# RX64M_SYSTEM_Pilot register map
File version: 1.0
RX64M_SYSTEM_Pilot peripheral registers generated from iodefine.h (pilot).
Registers are 8-bit, read-write, reset 0x0 unless marked. A register's access mark holds for its fields unless they carry their own. Offsets are from the block's base; lines under a group give offsets from that group; [hi:lo] are bit positions; {n}, {i} and the like mark numbered series; 'fields as' and 'values as' point back to an identical list; <NAME> marks a mode.

## Memory map
0x00080000 SYSTEM size 0xC2C0

## SYSTEM
Base 0x00080000
0x00 MDMONR 16-bit ro reset not defined
  [0] MD
0x02 MDSR 16-bit ro reset not defined
  [5] UBTS
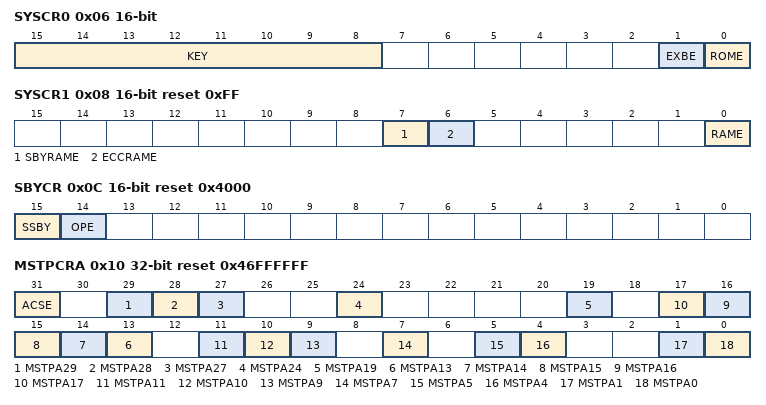
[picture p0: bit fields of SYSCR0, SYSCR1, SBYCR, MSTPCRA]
0x06 SYSCR0 16-bit reset not defined
  [15:8] KEY, [1] EXBE, [0] ROME
0x08 SYSCR1 16-bit reset 0xFF
  [7] SBYRAME, [6] ECCRAME, [0] RAME
0x0C SBYCR 16-bit reset 0x4000
  [15] SSBY, [14] OPE
0x10 MSTPCRA 32-bit reset 0x46FFFFFF
  [31] ACSE, [29] MSTPA29, [28] MSTPA28, [27] MSTPA27, [24] MSTPA24, [19] MSTPA19, [n] MSTPA{n} (n=13..17), [11] MSTPA11, [10] MSTPA10, [9] MSTPA9, [7] MSTPA7, [5] MSTPA5, [4] MSTPA4, [1] MSTPA1, [0] MSTPA0
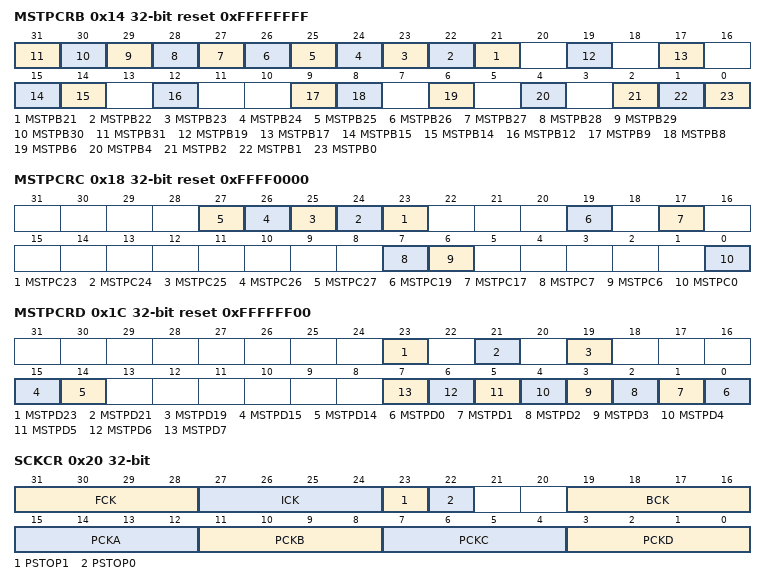
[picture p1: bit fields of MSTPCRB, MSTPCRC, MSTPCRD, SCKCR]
0x14 MSTPCRB 32-bit reset 0xFFFFFFFF
  [n] MSTPB{n} (n=21..31), [19] MSTPB19, [17] MSTPB17, [15] MSTPB15, [14] MSTPB14, [12] MSTPB12, [9] MSTPB9, [8] MSTPB8, [6] MSTPB6, [4] MSTPB4, [2] MSTPB2, [1] MSTPB1, [0] MSTPB0
0x18 MSTPCRC 32-bit reset 0xFFFF0000
  [n] MSTPC{n} (n=23..27), [19] MSTPC19, [17] MSTPC17, [7] MSTPC7, [6] MSTPC6, [0] MSTPC0
0x1C MSTPCRD 32-bit reset 0xFFFFFF00
  [23] MSTPD23, [21] MSTPD21, [19] MSTPD19, [15] MSTPD15, [14] MSTPD14, [n] MSTPD{n} (n=0..7)
0x20 SCKCR 32-bit
  [31:28] FCK, [27:24] ICK, [23] PSTOP1, [22] PSTOP0, [19:16] BCK, [15:12] PCKA, [11:8] PCKB, [7:4] PCKC, [3:0] PCKD
0x24 SCKCR2 16-bit reset 0x11
  [7:4] UCK
0x26 SCKCR3 16-bit
  [10:8] CKSEL
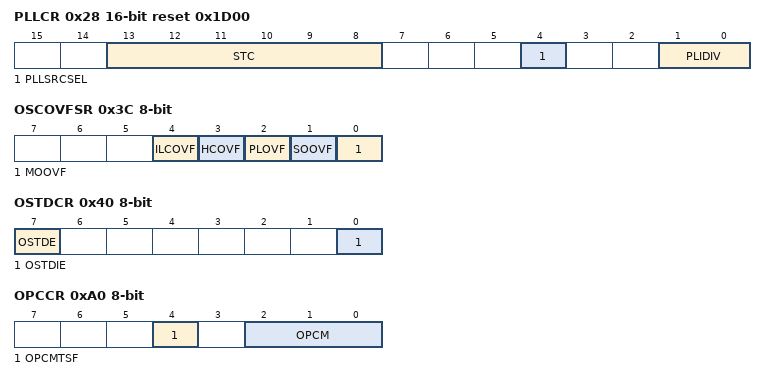
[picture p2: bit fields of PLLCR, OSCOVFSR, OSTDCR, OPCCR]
0x28 PLLCR 16-bit reset 0x1D00
  [13:8] STC, [4] PLLSRCSEL, [1:0] PLIDIV
0x2A PLLCR2 reset 0x1
  [0] PLLEN
0x30 BCKCR
  [0] BCLKDIV
0x32 MOSCCR reset 0x1
  [0] MOSTP
0x33 SOSCCR
  [0] SOSTP
0x34 LOCOCR
  [0] LCSTP
0x35 ILOCOCR reset 0x1
  [0] ILCSTP
0x36 HOCOCR reset not defined
  [0] HCSTP
0x37 HOCOCR2
  [1:0] HCFRQ
0x3C OSCOVFSR reset not defined
  [4] ILCOVF, [3] HCOVF, [2] PLOVF, [1] SOOVF, [0] MOOVF
0x40 OSTDCR
  [7] OSTDE, [0] OSTDIE
0x41 OSTDSR
  [0] OSTDF
0xA0 OPCCR
  [4] OPCMTSF, [2:0] OPCM
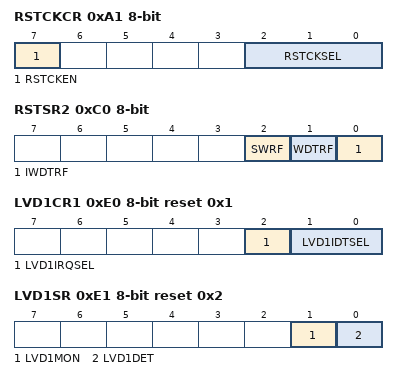
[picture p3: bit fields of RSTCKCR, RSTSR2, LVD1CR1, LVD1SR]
0xA1 RSTCKCR
  [7] RSTCKEN, [2:0] RSTCKSEL
0xA2 MOSCWTCR reset 0x53
  [7:0] MSTS
0xA3 SOSCWTCR reset 0x21
  [7:0] SSTS
0xC0 RSTSR2 reset not defined
  [2] SWRF, [1] WDTRF, [0] IWDTRF
0xC2 SWRR 16-bit
0xE0 LVD1CR1 reset 0x1
  [2] LVD1IRQSEL, [1:0] LVD1IDTSEL
0xE1 LVD1SR reset 0x2
  [1] LVD1MON, [0] LVD1DET
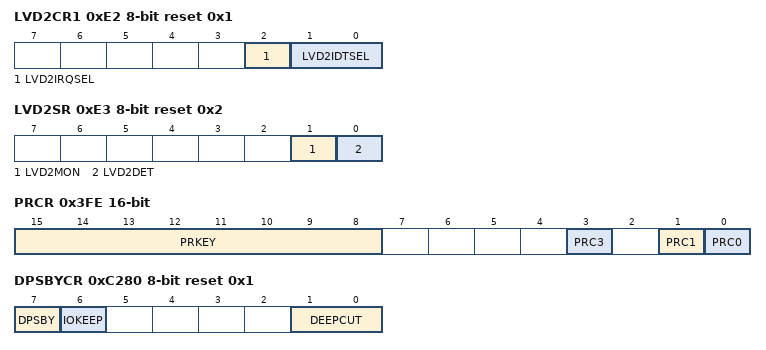
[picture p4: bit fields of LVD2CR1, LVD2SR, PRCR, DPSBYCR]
0xE2 LVD2CR1 reset 0x1
  [2] LVD2IRQSEL, [1:0] LVD2IDTSEL
0xE3 LVD2SR reset 0x2
  [1] LVD2MON, [0] LVD2DET
0x3FE PRCR 16-bit
  [15:8] PRKEY, [3] PRC3, [1] PRC1, [0] PRC0
0xC280 DPSBYCR reset 0x1
  [7] DPSBY, [6] IOKEEP, [1:0] DEEPCUT
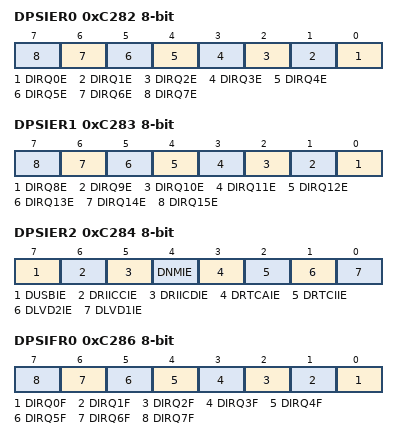
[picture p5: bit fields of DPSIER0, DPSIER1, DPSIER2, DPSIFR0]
0xC282 DPSIER0
  [n] DIRQ{n}E (n=0..7)
0xC283 DPSIER1
  [n-8] DIRQ{n}E (n=8..15)
0xC284 DPSIER2
  [7] DUSBIE, [6] DRIICCIE, [5] DRIICDIE, [4] DNMIE, [3] DRTCAIE, [2] DRTCIIE, [1] DLVD2IE, [0] DLVD1IE
0xC285 DPSIER3
  [0] DCANIE
0xC286 DPSIFR0
  [n] DIRQ{n}F (n=0..7)
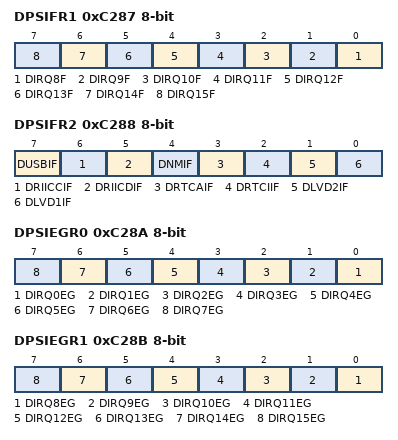
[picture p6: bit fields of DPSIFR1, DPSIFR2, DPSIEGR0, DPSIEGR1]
0xC287 DPSIFR1
  [n-8] DIRQ{n}F (n=8..15)
0xC288 DPSIFR2
  [7] DUSBIF, [6] DRIICCIF, [5] DRIICDIF, [4] DNMIF, [3] DRTCAIF, [2] DRTCIIF, [1] DLVD2IF, [0] DLVD1IF
0xC289 DPSIFR3
  [0] DCANIF
0xC28A DPSIEGR0
  [n] DIRQ{n}EG (n=0..7)
0xC28B DPSIEGR1
  [n-8] DIRQ{n}EG (n=8..15)
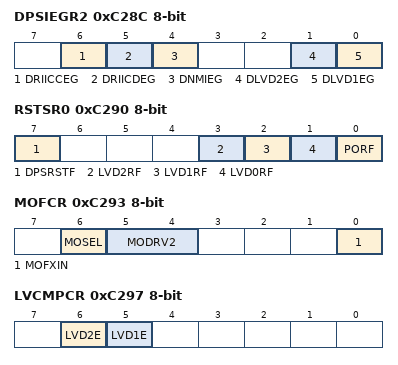
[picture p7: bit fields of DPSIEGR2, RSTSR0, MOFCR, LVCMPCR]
0xC28C DPSIEGR2
  [6] DRIICCEG, [5] DRIICDEG, [4] DNMIEG, [1] DLVD2EG, [0] DLVD1EG
0xC28D DPSIEGR3
  [0] DCANIEG
0xC290 RSTSR0 reset not defined
  [7] DPSRSTF, [3] LVD2RF, [2] LVD1RF, [1] LVD0RF, [0] PORF
0xC291 RSTSR1 reset not defined
  [0] CWSF
0xC293 MOFCR
  [6] MOSEL, [5:4] MODRV2, [0] MOFXIN
0xC294 HOCOPCR
  [0] HOCOPCNT
0xC297 LVCMPCR
  [6] LVD2E, [5] LVD1E
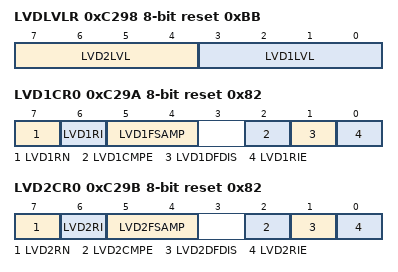
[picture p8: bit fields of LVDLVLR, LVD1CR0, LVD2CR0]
0xC298 LVDLVLR reset 0xBB
  [7:4] LVD2LVL, [3:0] LVD1LVL
0xC29A LVD1CR0 reset 0x82
  [7] LVD1RN, [6] LVD1RI, [5:4] LVD1FSAMP, [2] LVD1CMPE, [1] LVD1DFDIS, [0] LVD1RIE
0xC29B LVD2CR0 reset 0x82
  [7] LVD2RN, [6] LVD2RI, [5:4] LVD2FSAMP, [2] LVD2CMPE, [1] LVD2DFDIS, [0] LVD2RIE
{0xC2A0+i} DPSBKR{i} (i=0..31) reset not defined
